VERSION ""

NS_ :

BS_:

BU_: MINI_CELKA

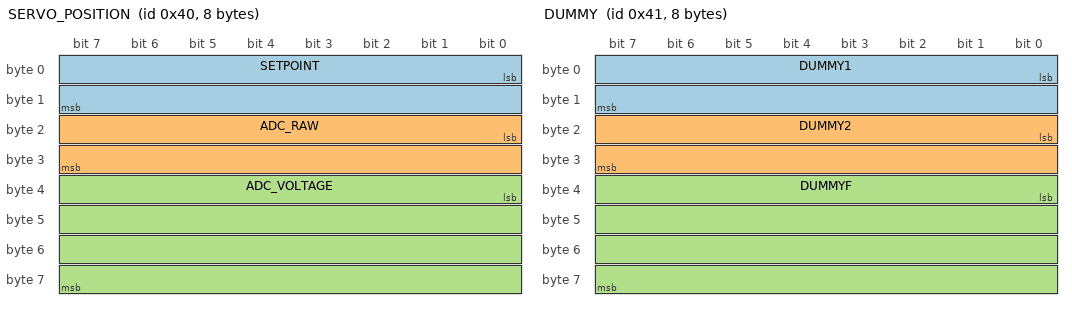
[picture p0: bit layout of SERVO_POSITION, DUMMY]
BO_ 64 SERVO_POSITION: 8 MINI_CELKA
	SG_ SETPOINT : 0|16@1+ (1,0) [900|2100] "" Vector__XXX
	SG_ ADC_RAW : 16|16@1+ (1,0) [0|4095] "" Vector__XXX
	SG_ ADC_VOLTAGE : 32|32@1+ (0.001,0) [0|3.3] "V" Vector__XXX

BO_ 65 DUMMY: 8 MINI_CELKA
	SG_ DUMMY1 : 0|16@1+ (1,0) [900|2100] "" Vector__XXX
	SG_ DUMMY2 : 16|16@1+ (1,0) [0|4095] "" Vector__XXX
	SG_ DUMMYF : 32|32@1+ (0.001,0) [0|3.3] "V" Vector__XXX
